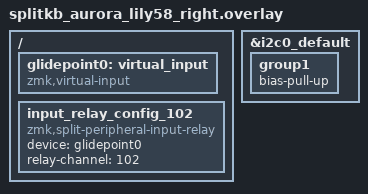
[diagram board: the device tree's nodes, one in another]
#include "splitkb_aurora_lily58.dtsi"

&i2c0_default {
    group1 {
      bias-pull-up;
    };
};

&glidepoint0 {
    status = "okay";
};

/ {
    /* THIS only makes keymap binding happy, nothing happens on peripheral side */
	glidepoint0: virtual_input {
		compatible = "zmk,virtual-input";
	};

    input_relay_config_102 {
        compatible = "zmk,split-peripheral-input-relay";

        /* peripheral side input device, used to... */
		/*  - be intecepted on peripheral; */
		/*  - and then, be resurrected as `zmk,virtual-device` on central; */
        device = <&glidepoint0>;

        /* channel id, used to be be transfered along with all input events. */
		/* NOTE 1: pick any 8bit integer. (1 - 255) */
		/* NOTE 2: should matching relay-channel on central overlay */
		relay-channel = <102>;
    };
};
